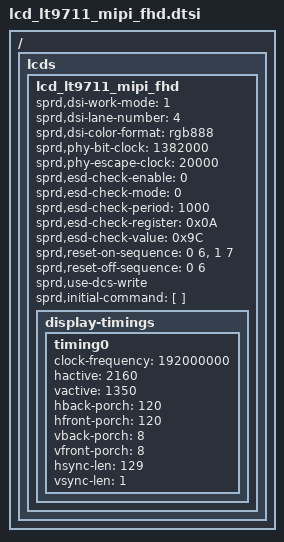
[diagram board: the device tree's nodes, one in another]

/*
 * tv105wum LCD config dtsi file for spreadtrum
 *
 * Copyright (C) 2021, Anhui Yunshu Zhihui Technology Co., Ltd.
 *
 * SPDX-License-Identifier: GPL-2.0-only
 */

/ { lcds {
	lcd_lt9711_mipi_fhd: lcd_lt9711_mipi_fhd {

		sprd,dsi-work-mode = <1>; /* video burst mode*/
		sprd,dsi-lane-number = <4>;
		sprd,dsi-color-format = "rgb888";

		sprd,phy-bit-clock = <1382000>;	/* kbps */
		sprd,phy-escape-clock = <20000>;/* kHz */

		/*
		sprd,width-mm = <68>;
		sprd,height-mm = <121>;
		*/

		sprd,esd-check-enable = <0>;
		sprd,esd-check-mode = <0>;
		sprd,esd-check-period = <1000>;
		sprd,esd-check-register = <0x0A>;
		sprd,esd-check-value = <0x9C>;

		sprd,reset-on-sequence = <0 6>, <1 7>;
		sprd,reset-off-sequence = <0 6>;

		sprd,use-dcs-write;
		sprd,initial-command = [

			];
/*
		sprd,sleep-in-command = [
            05 0A 00 01 28
            05 65 00 01 10
			];
*/
/*		sprd,sleep-out-command = [
            13 64 00 01 11
            13 32 00 01 29
			];
*/



		display-timings {
			timing0 {
				clock-frequency = <192000000>;
				hactive = <2160>;
				vactive = <1350>;
				hback-porch = <120>;
				hfront-porch = <120>;
				vback-porch = <8>;
				vfront-porch = <8>;
				hsync-len = <129>;
				vsync-len = <1>;
			};
		};
	};
};};
